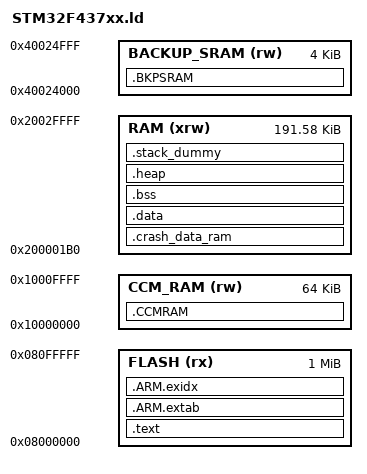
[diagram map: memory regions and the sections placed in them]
#if !defined(MBED_APP_START)
  #define MBED_APP_START 0x08000000
#endif

#if !defined(MBED_APP_SIZE)
  #define MBED_APP_SIZE 1024k
#endif

M_CRASH_DATA_RAM_SIZE = 0x100;

#if !defined(MBED_BOOT_STACK_SIZE)
    #define MBED_BOOT_STACK_SIZE 0x400
#endif

STACK_SIZE = MBED_BOOT_STACK_SIZE;

/* Linker script to configure memory regions. */
/* 0x1AC resevered for vectors; 8-byte aligned = 0x1B0 (0x1AC + 0x4)*/
MEMORY
{ 
RAM (xrw)        : ORIGIN = 0x200001B0, LENGTH = 192K - 0x1B0 /* 0x1AC+0x4 is to leave room for vectors */
CCM_RAM (rw)     : ORIGIN = 0x10000000, LENGTH = 64K
BACKUP_SRAM (rw) : ORIGIN = 0x40024000, LENGTH = 4096
FLASH (rx)       : ORIGIN = MBED_APP_START, LENGTH = MBED_APP_SIZE
}

/* Linker script to place sections and symbol values. Should be used together
 * with other linker script that defines memory regions FLASH and RAM.
 * It references following symbols, which must be defined in code:
 *   Reset_Handler : Entry of reset handler
 * 
 * It defines following symbols, which code can use without definition:
 *   __exidx_start
 *   __exidx_end
 *   __etext
 *   __data_start__
 *   __preinit_array_start
 *   __preinit_array_end
 *   __init_array_start
 *   __init_array_end
 *   __fini_array_start
 *   __fini_array_end
 *   __data_end__
 *   __bss_start__
 *   __bss_end__
 *   __end__
 *   end
 *   __HeapLimit
 *   __StackLimit
 *   __StackTop
 *   __stack
 *   _estack
 */
ENTRY(Reset_Handler)

SECTIONS
{
    .text :
    {
        KEEP(*(.isr_vector))
        *(.text*)
        KEEP(*(.init))
        KEEP(*(.fini))

        /* .ctors */
        *crtbegin.o(.ctors)
        *crtbegin?.o(.ctors)
        *(EXCLUDE_FILE(*crtend?.o *crtend.o) .ctors)
        *(SORT(.ctors.*))
        *(.ctors)

        /* .dtors */
        *crtbegin.o(.dtors)
        *crtbegin?.o(.dtors)
        *(EXCLUDE_FILE(*crtend?.o *crtend.o) .dtors)
        *(SORT(.dtors.*))
        *(.dtors)

        *(.rodata*)

        KEEP(*(.eh_frame*))
    } > FLASH

    .ARM.extab :
    {
        *(.ARM.extab* .gnu.linkonce.armextab.*)
    } > FLASH

    __exidx_start = .;
    .ARM.exidx :
    {
        *(.ARM.exidx* .gnu.linkonce.armexidx.*)
    } > FLASH
    __exidx_end = .;

    __etext = .;
    _sidata = .;
    
    .crash_data_ram :
    {
        . = ALIGN(8);
        __CRASH_DATA_RAM__ = .;
        __CRASH_DATA_RAM_START__ = .; /* Create a global symbol at data start */
        KEEP(*(.keep.crash_data_ram))
        *(.m_crash_data_ram)     /* This is a user defined section */
        . += M_CRASH_DATA_RAM_SIZE;
        . = ALIGN(8);
        __CRASH_DATA_RAM_END__ = .; /* Define a global symbol at data end */
    } > RAM

    .data : AT (__etext)
    {
        __data_start__ = .;
        _sdata = .;
        *(vtable)
        *(.data*)

        . = ALIGN(8);
        /* preinit data */
        PROVIDE_HIDDEN (__preinit_array_start = .);
        KEEP(*(.preinit_array))
        PROVIDE_HIDDEN (__preinit_array_end = .);

        . = ALIGN(8);
        /* init data */
        PROVIDE_HIDDEN (__init_array_start = .);
        KEEP(*(SORT(.init_array.*)))
        KEEP(*(.init_array))
        PROVIDE_HIDDEN (__init_array_end = .);


        . = ALIGN(8);
        /* finit data */
        PROVIDE_HIDDEN (__fini_array_start = .);
        KEEP(*(SORT(.fini_array.*)))
        KEEP(*(.fini_array))
        PROVIDE_HIDDEN (__fini_array_end = .);

        KEEP(*(.jcr*))
        . = ALIGN(8);
        /* All data end */
        __data_end__ = .;
        _edata = .;

    } > RAM

    .bss :
    {
        . = ALIGN(8);
        __bss_start__ = .;
        _sbss = .;
        *(.bss*)
        *(COMMON)
        . = ALIGN(8);
        __bss_end__ = .;
        _ebss = .;
    } > RAM

    .heap (COPY):
    {
        __end__ = .;
        end = __end__;
        *(.heap*)
        . = ORIGIN(RAM) + LENGTH(RAM) - STACK_SIZE;
        __HeapLimit = .;
    } > RAM

    /* .stack_dummy section doesn't contains any symbols. It is only
     * used for linker to calculate size of stack sections, and assign
     * values to stack symbols later */
    .stack_dummy (COPY):
    {
        *(.stack*)
    } > RAM

    /* Set stack top to end of RAM, and stack limit move down by
     * size of stack_dummy section */
    __StackTop = ORIGIN(RAM) + LENGTH(RAM);
    _estack = __StackTop;
    __StackLimit = __StackTop - STACK_SIZE;
    PROVIDE(__stack = __StackTop);

    /* Check if data + heap + stack exceeds RAM limit */
    ASSERT(__StackLimit >= __HeapLimit, "region RAM overflowed with stack")

    /* Code can explicitly ask for data to be 
       placed into CCMRAM which will be left
       uninitialized. 
    */
    .CCMRAM (NOLOAD):
    {
        Image$$RW_IRAM2$$Base = . ;
        *(CCMRAM)
        Image$$RW_IRAM2$$ZI$$Limit = .;
    } > CCM_RAM

    /* Backup SRAM, requires unlocking before access */
    .BKPSRAM (NOLOAD):
    {
        Image$$RW_IRAM3$$Base = . ;
        *(BKPSRAM)
        Image$$RW_IRAM3$$ZI$$Limit = .;
    } > BACKUP_SRAM
}
